# Template register map
Vendor: VendorName Co.Ltd; Series: SeriesName; File version: 1.2
CPU: CM7 r0p1, little endian, MPU, FPU, 4 interrupt priority bits
Registers are 32-bit, read-write, no defined reset value unless marked. A register's access mark holds for its fields unless they carry their own. Offsets are from the block's base; [hi:lo] are bit positions; 'fields as' and 'values as' point back to an identical list.

## IWDG1 — Independent Watchdog 1
Base 0x400C3000
0x00 RR — IWDG refresh register
  [7:0] CMD — IWDG CMD[7:0] bit: IWDG refresh command
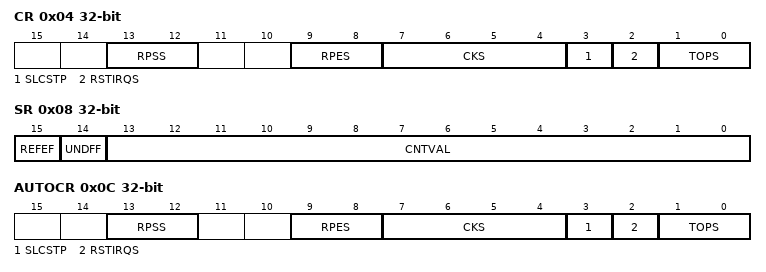
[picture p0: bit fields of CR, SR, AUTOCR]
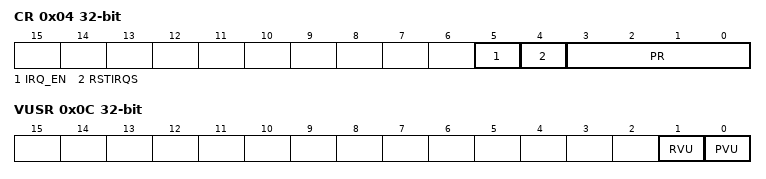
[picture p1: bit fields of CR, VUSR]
0x04 CR — IWDG control register
  [13:12] RPSS — IWDG RPSS[1:0] bit: window start position select bit
  [9:8] RPES — IWDG RPES[1:0] bit: window end position select bit
  [7:4] CKS — IWDG CKS[3:0] bit: clock frequency division ratio select bit
  [3] SLCSTP — IWDG SLCSTP bit: counting stop control in low-power mode
  [2] RSTIRQS — IWDG RSTIRQS bit: reset interrupt request select
  [1:0] TOPS — IWDG TOPS[1:0] bit: timeout period select bit
0x08 SR — IWDG status register
  [15] REFEF — IWDG REFEF bit: refresh error flag
  [14] UNDFF — IWDG UNDFF bit: underflow flag
  [13:0] CNTVAL ro — IWDG CNTVAL[13:0] bit: counter value
0x0C AUTOCR ro — IWDG hardware automatic control register
  fields as CR
0x10 INTSR ro — IWDG interrupt status register
  [0] IWDG1INT — IWDG IWDG1INT bit: IWDG interrupt flag bit
0x14 INTCLR wo — IWDG interruption clear register
  [0] IWDG1INTCLR — IWDG IWDG1INTCLR bit: IWDG interrupt clear bit

## IWDG2 — Independent Watchdog 2
Base 0x40021000
0x00 KR wo — IWDG key register
  [15:0] KEY — IWDG2 KEY[15:0] bit: only when 0xAAAA is written can this register be written
0x04 CR — IWDG control register
  [5] IRQ_EN — IWDG2 IRQ_EN bit: interrupt request bit
  [4] RSTIRQS — IWDG2 RSTIRQS bit: reset interrupt mode select bit
  [3:0] PR — IWDG2 PR[3:0] bit: frequency division coefficient select bit
0x08 RLR — IWDG reload register
  [11:0] RL — IWDG2 RL[11:0] bit: watchdog counter reload value
0x0C VUSR ro — IWDG update status register
  [1] RVU — IWDG2 RVU bit: watchdog counter reload value update
  [0] PVU — IWDG2 PVU bit: watchdog prescaler value update
0x10 INTSR ro — IWDG interrupt status register
  [2] IWDG2INT — IWDG2 IWDG2INT bit: IWDG2 interrupt flag bit
0x14 INTCLR wo — IWDG interrupt clear register
  [2] INT_CLR — IWDG2 INT_CLR bit: IWDG2 interrupt clear bit

## LPTIM — Low Power Timer
Base 0x40023000
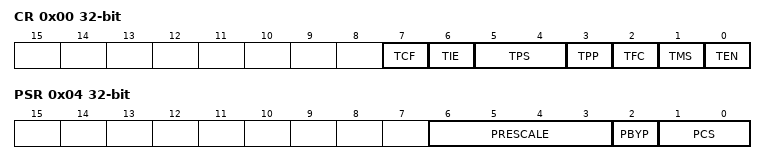
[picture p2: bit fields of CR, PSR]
0x00 CR — LPTIM control status register
  [7] TCF — LPTIM TCF bit: timer compare flag
  [6] TIE — LPTIM TIE bit: timer interrupt enable
  [5:4] TPS — LPTIM TPS[1:0] bit: timer pin select
  [3] TPP — LPTIM TPP bit: timer pin polarity
  [2] TFC — LPTIM TFC bit: timer free-running counter
  [1] TMS — LPTIM TMS bit: timer mode select
  [0] TEN — LPTIM TEN bit: timer enable
0x04 PSR — LPTIM prescale register
  [6:3] PRESCALE — LPTIM PRESCALE[3:0] bit: prescale/filter value
  [2] PBYP — LPTIM PBYP bit: prescale/filter bypass
  [1:0] PCS — LPTIM PCS[1:0] bit: prescale/filter clock select
0x08 CMR — LPTIM compare register
  [15:0] COMPARE — LPTIM COMPARE[15:0] bit: compare value
0x0C CNT — LPTIM counter register
  [15:0] COUNTER — LPTIM COUNTER[15:0] bit: counter value

## MCM — Miscellaneous Control Module
Base 0xE0080000
0x00 CPUID ro — CPU CPUID register
  [1:0] CPUID — MCM CPUID[1:0] bit: CPU serial number
0x0C CPCR — CPU MCM control register
  [0] AHBSPRI — MCM AHBSPRI bit: the access priority of AHBS
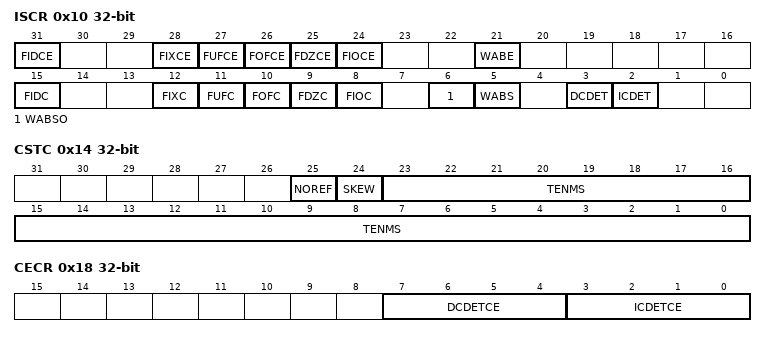
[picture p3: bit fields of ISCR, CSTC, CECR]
0x10 ISCR — CPU MCM interrupt control status register
  [31] FIDCE — MCM FIDCE bit: FPU input irregular interruption enable
  [28] FIXCE — MCM FIXCE bit: FPU inexact interruption enable
  [27] FUFCE — MCM FUFCE bit: FPU underflow interruption enable
  [26] FOFCE — MCM FOFCE bit: FPU overflow interruption enable
  [25] FDZCE — MCM FDZCE bit: FPU division by zero interruption enable
  [24] FIOCE — MCM FIOCE bit: FPU invalid operation interrupt enable
  [21] WABE — MCM WABE bit: TCM write abort interruption enable
  [15] FIDC ro — MCM FIDC bit: FPU input irregular interruption status
  [12] FIXC ro — MCM FIXC bit: FPU inexact interruption status
  [11] FUFC ro — MCM FUFC bit: FPU underflow interruption status
  [10] FOFC ro — MCM FOFC bit: FPU overflow interruption status
  [9] FDZC ro — MCM FDZC bit: FPU division by zero interruption status
  [8] FIOC ro — MCM FIOC bit: FPU invalid operation interrupt status
  [6] WABSO ro — MCM WABSO bit: write abort on slave overrun
  [5] WABS — MCM WABS bit: write abort on slave
  [3] DCDET — MCM DCDET bit: CPU D-cache error information
  [2] ICDET — MCM ICDET bit: CPU I-cache error information
0x14 CSTC — CPU MCM tick clock calib register
  [25] NOREF — MCM NOREF bit: There are other reference clocks
  [24] SKEW — MCM SKEW bit: Reference clock 10ms accurate
  [23:0] TENMS — MCM TENMS[23:0] bit: Number of cycles required for 10ms is for systick
0x18 CECR — CPU MCM cache error register
  [7:4] DCDETCE — MCM DCDETCE[3:0] bit: D-Cache error interruption enable
  [3:0] ICDETCE — MCM ICDETCE[3:0] bit: I-Cache error interruption enable
